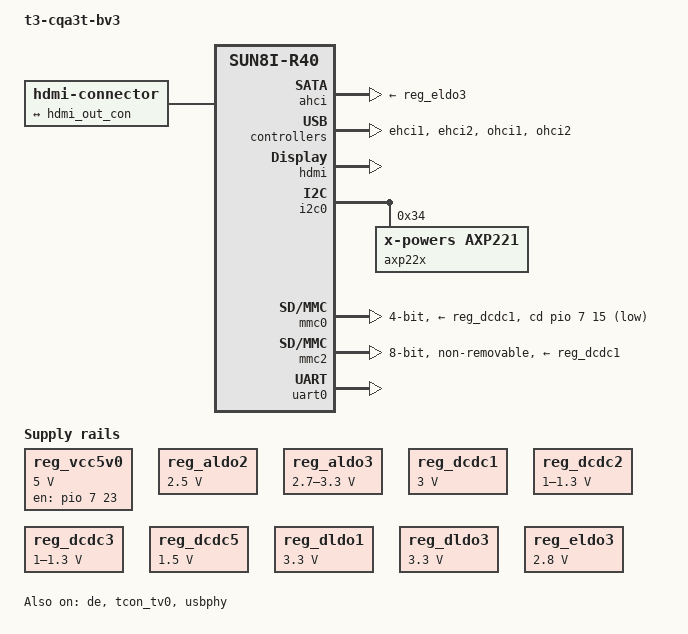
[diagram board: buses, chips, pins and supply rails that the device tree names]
/dts-v1/;
#include "sun8i-r40.dtsi"
#include "sun8i-r40-cpu-opp.dtsi"
#include <dt-bindings/gpio/gpio.h>
/ {
	model = "t3-cqa3t-bv3";
	compatible = "qihua,t3-cqa3t-bv3", "allwinner,sun8i-t3",
		     "allwinner,sun8i-r40";
	aliases {
		serial0 = &uart0;
	};
	chosen {
		stdout-path = "serial0:115200n8";
	};
	connector {
		compatible = "hdmi-connector";
		type = "a";
		port {
			hdmi_con_in: endpoint {
				remote-endpoint = <&hdmi_out_con>;
			};
		};
	};
	reg_vcc5v0: vcc5v0 {
		compatible = "regulator-fixed";
		regulator-name = "vcc5v0";
		regulator-min-microvolt = <5000000>;
		regulator-max-microvolt = <5000000>;
		gpio = <&pio 7 23 GPIO_ACTIVE_HIGH>;  
		enable-active-high;
	};
};
&ahci {
	ahci-supply = <&reg_dldo4>;
	phy-supply = <&reg_eldo3>;
	status = "okay";
};
&cpu0 {
	cpu-supply = <&reg_dcdc2>;
};
&de {
	status = "okay";
};
&ehci1 {
	status = "okay";
};
&ehci2 {
	status = "okay";
};
&hdmi {
	status = "okay";
};
&hdmi_out {
	hdmi_out_con: endpoint {
		remote-endpoint = <&hdmi_con_in>;
	};
};
&i2c0 {
	status = "okay";
	axp22x: pmic@34 {
		compatible = "x-powers,axp221";
		reg = <0x34>;
		interrupt-parent = <&nmi_intc>;
		interrupts = <0 IRQ_TYPE_LEVEL_LOW>;
	};
};
#include "axp22x.dtsi"
&mmc0 {
	vmmc-supply = <&reg_dcdc1>;
	bus-width = <4>;
	cd-gpios = <&pio 7 15 GPIO_ACTIVE_LOW>;  
	status = "okay";
};
&mmc2 {
	vmmc-supply = <&reg_dcdc1>;
	vqmmc-supply = <&reg_dcdc1>;
	bus-width = <8>;
	non-removable;
	status = "okay";
};
&ohci1 {
	status = "okay";
};
&ohci2 {
	status = "okay";
};
&reg_aldo2 {
	regulator-always-on;
	regulator-min-microvolt = <2500000>;
	regulator-max-microvolt = <2500000>;
	regulator-name = "vcc-pa";
};
&reg_aldo3 {
	regulator-always-on;
	regulator-min-microvolt = <2700000>;
	regulator-max-microvolt = <3300000>;
	regulator-name = "avcc";
};
&reg_dcdc1 {
	regulator-always-on;
	regulator-min-microvolt = <3000000>;
	regulator-max-microvolt = <3000000>;
	regulator-name = "vcc-3v0";
};
&reg_dcdc2 {
	regulator-always-on;
	regulator-min-microvolt = <1000000>;
	regulator-max-microvolt = <1300000>;
	regulator-name = "vdd-cpu";
};
&reg_dcdc3 {
	regulator-always-on;
	regulator-min-microvolt = <1000000>;
	regulator-max-microvolt = <1300000>;
	regulator-name = "vdd-sys";
};
&reg_dcdc5 {
	regulator-always-on;
	regulator-min-microvolt = <1500000>;
	regulator-max-microvolt = <1500000>;
	regulator-name = "vcc-dram";
};
&reg_dldo1 {
	regulator-always-on;
	regulator-min-microvolt = <3300000>;
	regulator-max-microvolt = <3300000>;
	regulator-name = "vcc-pg";
};
&reg_dldo3 {
	regulator-always-on;
	regulator-min-microvolt = <3300000>;
	regulator-max-microvolt = <3300000>;
	regulator-name = "vcc-dldo3";
};
&reg_eldo3 {
	regulator-always-on;
	regulator-min-microvolt = <2800000>;
	regulator-max-microvolt = <2800000>;
	regulator-name = "vcc-pe";
};
&tcon_tv0 {
	status = "okay";
};
&uart0 {
	pinctrl-names = "default";
	pinctrl-0 = <&uart0_pb_pins>;
	status = "okay";
};
&usbphy {
	usb1_vbus-supply = <&reg_vcc5v0>;
	usb2_vbus-supply = <&reg_vcc5v0>;
	status = "okay";
};
